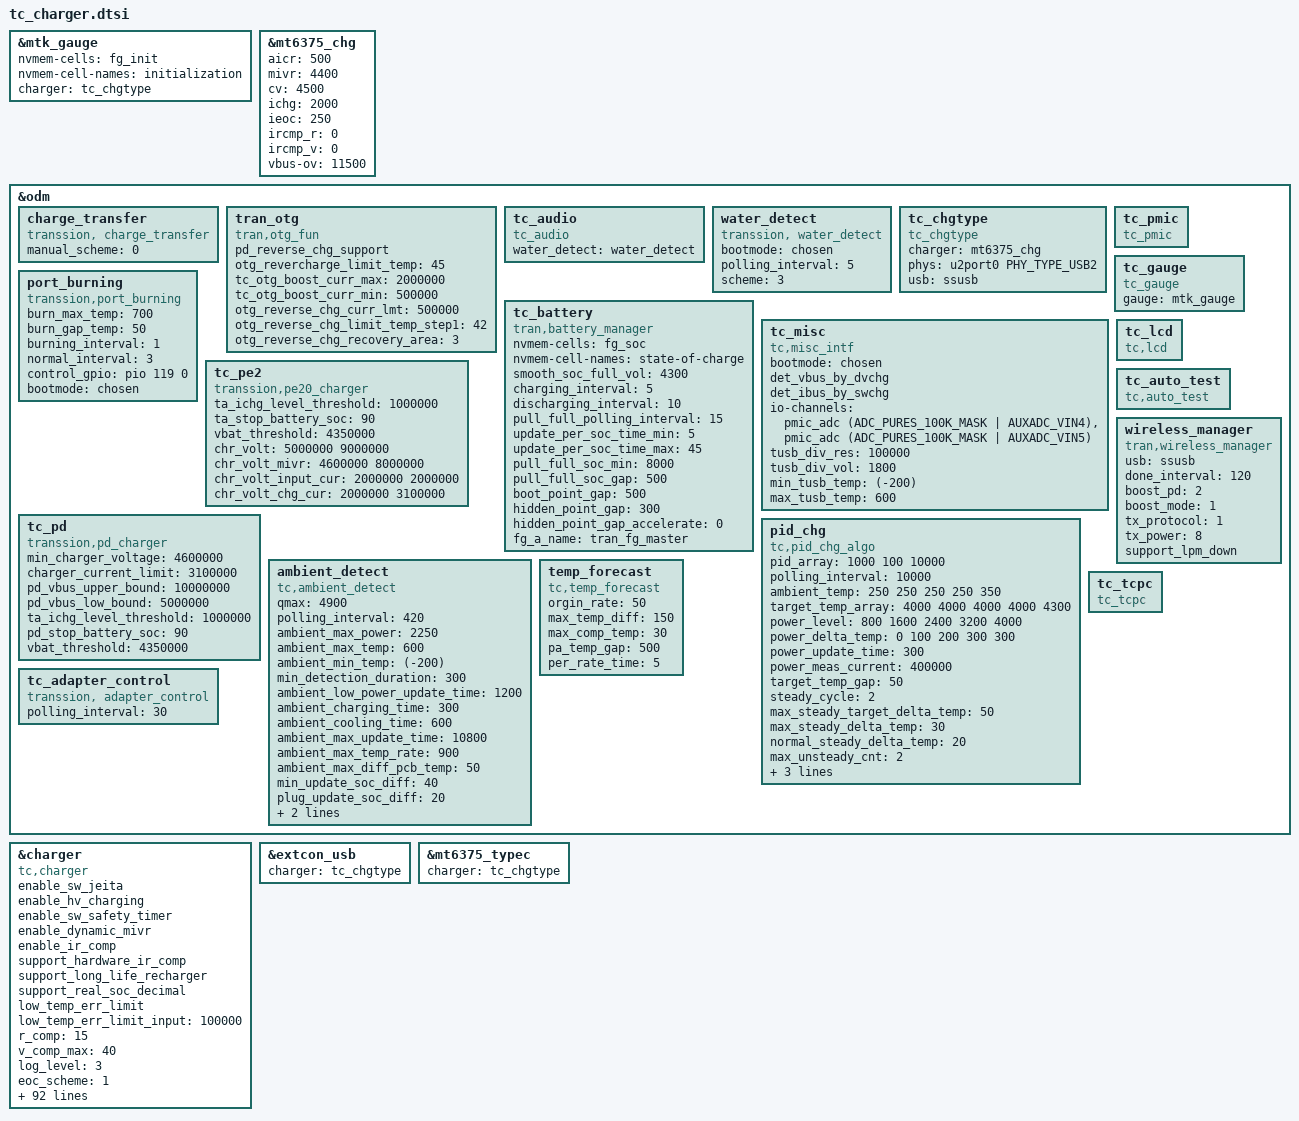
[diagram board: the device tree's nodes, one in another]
#include <dt-bindings/iio/mt635x-auxadc.h>
#include <dt-bindings/iio/adc/mediatek,mt6375_adc.h>

&mtk_gauge {
	nvmem-cells = <&fg_init>;
	nvmem-cell-names = "initialization";
};

&mt6375_chg {
	aicr = <500>;
	mivr = <4400>;
	cv = <4500>;
	ichg = <2000>;
	ieoc = <250>;
	ircmp_r = <0>;
	ircmp_v = <0>;
	vbus-ov = <11500>;
};

&odm {
	charge_transfer: charge_transfer {
		compatible = "transsion, charge_transfer";
		status = "okay";
		manual_scheme = <0>;
	};

	tran_otg: tran_otg {
		compatible = "tran,otg_fun";
		status = "okay";
		/* support_otg_dcp; */
		/* otg_dcp_by_pmic; */
		/* support_ext_otg; */
		pd_reverse_chg_support;
		otg_revercharge_limit_temp = <45>;
		tc_otg_boost_curr_max = <2000000>; /* 10W config 2000000,6W config 1200000 */
		tc_otg_boost_curr_min = <500000>;
		otg_reverse_chg_curr_lmt = <500000>;
		otg_reverse_chg_limit_temp_step1 = <42>;
		otg_reverse_chg_recovery_area = <3>;
	};

	tc_audio: tc_audio {
		compatible = "tc_audio";
		status = "okay";
		water_detect = <&water_detect>;
	};

	water_detect: water_detect {
		status = "okay";
		compatible = "transsion, water_detect";
		bootmode = <&chosen>;
		polling_interval = <5>;

		/*	0:SUBPMIC USB_ID detect
			1:GPIO detect
			2:GPIO detect--GPIO sel 1--- GPIO sel sbu1/2
			3:WAS4783 detect
			4:SUBPMIC USB_ID detect--GPIO sel 1
			5:SUBPMIC USB_ID detect--GPIO sel 1--- GPIO sel sbu1/2
		*/
		scheme = <3>;
	};

	tc_chgtype: tc_chgtype {
		compatible = "tc_chgtype";
		charger = <&mt6375_chg>;
		phys = <&u2port0 PHY_TYPE_USB2>;
		phy-names = "usb2-phy";
		usb = <&ssusb>;
		status = "okay";
	};

	tc_pmic: tc_pmic {
		compatible = "tc_pmic";
		status = "okay";
		/* The current project is not in use */
		//io-channels = <&pmic_auxadc AUXADC_VCDT>;
		//io-channel-names = "pmic_vbus";
		//pmic = <&pmic>;

		//io-channels = <&mt6375_auxadc AUXADC_VCDT>;
		//io-channels = <&mt6375_adc MT6375_ADC_CHGVIN>;
	};

	tc_gauge: tc_gauge {
		compatible = "tc_gauge";
		gauge = <&mtk_gauge>;
		status = "okay";
	};

	tc_battery: tc_battery {
		compatible = "tran,battery_manager";
		status = "okay";
		nvmem-cells = <&fg_soc>;
		nvmem-cell-names = "state-of-charge";
		smooth_soc_full_vol = <4300>;               //unit: mV
		charging_interval = <5>;                    //unit: S
		discharging_interval = <10>;                //unit: S
		pull_full_polling_interval = <15>;          //unit: S
		update_per_soc_time_min = <5>;              //unit: S
		update_per_soc_time_max = <45>;             //unit: S
		pull_full_soc_min = <8000>;                 //unit: 0.01
		pull_full_soc_gap = <500>;                  //unit: 0.01
		boot_point_gap = <500>;                     //unit: 0.01
		hidden_point_gap = <300>;                   //unit: 0.01
		hidden_point_gap_accelerate = <0>;
		fg_a_name = "tran_fg_master";
		/* dual battery  */
		/* fg_b_name = "tran_fg_slave"; */
		/* dual_fuel_gauge; */
		/* sw_cv_gap = <15>; */
		/* max_voltage_diff = <250>; */
		/* start_balance_vol_diff = <150>; */
		/* balance_step = <5>; */
		/* balance_step_cur = <500>; */
		/* min_lmt_chg_cur = <500>; */
	};

	tc_misc: tc_misc {
		compatible = "tc,misc_intf";
		bootmode = <&chosen>;
		det_vbus_by_dvchg;
		det_ibus_by_swchg;
		/* det_tusb_by_swchg; */
		io-channels = <&pmic_adc (ADC_PURES_100K_MASK | AUXADC_VIN4)>,<&pmic_adc (ADC_PURES_100K_MASK | AUXADC_VIN5)>;
		io-channel-names = "tusb","tport";
		tusb_div_res = <100000>;
		tusb_div_vol = <1800>;
		min_tusb_temp = <(-200)>;
		max_tusb_temp = <600>;
	};

	port_burning:port_burning {
		compatible = "transsion,port_burning";
		burn_max_temp = <700>;
		burn_gap_temp = <50>;
		burning_interval = <1>;
		normal_interval = <3>;
		control_gpio = <&pio 119 0>;
		bootmode= <&chosen>;
	};

	tc_lcd: tc_lcd {
		compatible = "tc,lcd";
	};

	tc_pe2:tc_pe2 {
		compatible = "transsion,pe20_charger";
		status = "okay";

		/* TC30 */
		ta_ichg_level_threshold = <1000000>; /* uA */
		ta_stop_battery_soc = <90>;
		vbat_threshold = <4350000>;

		chr_volt = <5000000 9000000>;
		chr_volt_mivr = <4600000 8000000>;
		chr_volt_input_cur = <2000000 2000000>;
		chr_volt_chg_cur = <2000000 3100000>;
	};

	tc_pd:tc_pd {
		compatible = "transsion,pd_charger";
		status = "okay";

		/* PD_FIX */
		min_charger_voltage = <4600000>; /* uV */
		charger_current_limit = <3100000>;
		pd_vbus_upper_bound = <10000000>;
		pd_vbus_low_bound = <5000000>;
		ta_ichg_level_threshold = <1000000>;
		pd_stop_battery_soc = <90>;
		vbat_threshold = <4350000>;
	};

	tc_auto_test: tc_auto_test {
	            compatible = "tc,auto_test";
	            status = "okay";
	};

	wireless_manager:wireless_manager {
		compatible = "tran,wireless_manager";
		usb = <&ssusb>;
		done_interval = <120>;
		boost_pd = <2>;
		boost_mode = /bits/ 8 <1>;
		tx_protocol = /bits/ 8 <1>;
		tx_power =  /bits/ 8 <8>;
		support_lpm_down;
		status = "okay";
	};

	pid_chg:pid_chg{
		compatible = "tc,pid_chg_algo";
		pid_array = <1000 100 10000>;           //KP KI KD
		polling_interval = <10000>;                     //The minimum time for each cycle
		ambient_temp = <250 250 250 250 350>;
		target_temp_array = <4000 4000 4000 4000 4300>;
		power_level = <800 1600 2400 3200 4000>;        //The average power consumption in the on-screen mode
		power_delta_temp = <0 100 200 300 300>;         //Temperature corresponding to the average power consumption in the on-screen mode
		power_update_time = <300>;                      //Average power update time in the on-screen mode
		power_meas_current = <400000>;                  //ibus current when the average power is measured in the on-screen mode
		target_temp_gap = <50>;
		steady_cycle = <2>;
		max_steady_target_delta_temp = <50>;
		max_steady_delta_temp = <30>;
		normal_steady_delta_temp = <20>;
		max_unsteady_cnt = <2>;
		max_target_temp = <4400>;
		//support_ibus_measure;
		ibus_measure_power_update_time = <60>;
		delta_current_max = <500000>;
	};

	ambient_detect:ambient_detect{
		compatible = "tc,ambient_detect";
		qmax = <4900>;
		polling_interval = <420>;
		ambient_max_power = <2250>;
		ambient_max_temp = <600>;
		ambient_min_temp = <(-200)>;
		min_detection_duration = <300>;
		ambient_low_power_update_time = <1200>;
		ambient_charging_time = <300>;
		ambient_cooling_time = <600>;
		ambient_max_update_time = <10800>;
		ambient_max_temp_rate = <900>;
		ambient_max_diff_pcb_temp = <50>;
		min_update_soc_diff = <40>;
		plug_update_soc_diff = <20>;
		power_level = <400 800 1200 1600 2000>;
		power_delta_temp = <0 10 20 30 40>;
	};

	temp_forecast:temp_forecast{
		compatible = "tc,temp_forecast";
		orgin_rate = <50>;
		max_temp_diff = <150>;
		max_comp_temp = <30>;
		pa_temp_gap = <500>;
		per_rate_time = <5>;
	};

	tc_tcpc:tc_tcpc{
		compatible = "tc_tcpc";
		status = "okay";
	};

	tc_adapter_control:tc_adapter_control {
		compatible = "transsion, adapter_control";
		polling_interval = <30>;
		status = "okay";
	};
};

&charger{
	compatible = "tc,charger";
	enable_sw_jeita;
	enable_hv_charging;
	enable_sw_safety_timer;
	/* charger_unlimited; */
	enable_dynamic_mivr;
	enable_ir_comp;
	/* support_reset_eoc; */
	support_hardware_ir_comp;
	support_long_life_recharger;
	support_real_soc_decimal;
	low_temp_err_limit;
	low_temp_err_limit_input = <100000>;
	r_comp = <15>;
	v_comp_max = <40>;
	log_level = <3>;
	eoc_scheme = <1>;
	aging_start_uisoc = <70>;
	aging_stop_uisoc = <75>;
	kom_start_uisoc = <40>;
	kom_stop_uisoc = <70>;
	batt_over_heat_temp = <60>;
	batt_over_cold_temp = <(-20)>;
	polling_interval = <20>;
	support_si_bat;
	si_bat_cycle_def = <100  200 99999>;
	si_bat_cycle_vol = <3000 3100 3200>;
	min_charger_voltage = <4400000>;
	min_charger_current = <1000000>;
	wireless_min_charger_current = <400000>;
	ftm_cp_num = <2>;
	sw_eoc_cv_gap = <20>;
	support_alg = "pe5", "pd", "pe20";

	tbat_temp = <(-100) 15 35 38 40 42 43 44 55 60 65 70>;
	tbat_ichg = <0 0 500000 800000 1000000 1500000 1700000 2000000 2400000 2400000 2400000 2400000>;
	tbat_temp_gap = <1>;

	tpcb_temp = <(-100) 15 30 35 37 39 41 45 55 60 65 70>;
	tpcb_ichg = <0 0 0 200000 300000 500000 700000 900000 1300000 1500000 2000000 2000000>;
	tpcb_temp_gap = <1>;

	tpa_temp = <(-100) 15 30 35 37 39 41 45 55 60 65 70>;
	tpa_ichg = <0 0 0 200000 300000 500000 700000 900000 1300000 1500000 2000000 2000000>;
	tpa_temp_gap = <1>;

	batt_ht_temp = <53 55 58>;
	batt_ht_rec_temp = <0 54 54>;
	batt_ht_code = <0  (1 << 11) (1 << 10)>;
	batt_ht_vote_hiz = <0 0 0>;
	batt_ht_vote_discharge = <0 1 1>;
	batt_ht_vote_icon = <0 1 1>;

	batt_lt_temp = <0 (-19) (-19)>;
	batt_lt_rec_temp = <0 (-17) (-17)>;
	batt_lt_code = <0 0 (1 << 12 | 1 << 7)>;
	batt_lt_vote_hiz = <0 0 0>;
	batt_lt_vote_discharge = <0 1 1>;
	batt_lt_vote_icon = <0 1 1>;

	kpoc_batt_ht_temp = <53 55 58>;
	kpoc_batt_ht_rec_temp = <0 54 54>;
	kpoc_batt_ht_code = <0 (1 << 11) (1 << 10)>;
	kpoc_batt_ht_vote_hiz = <0 0 0>;
	kpoc_batt_ht_vote_discharge = <0 1 1>;
	kpoc_batt_ht_vote_icon = <0 1 1>;

	kpoc_batt_lt_temp = <0 (-19) (-19)>;
	kpoc_batt_lt_rec_temp = <0 (-17) (-17)>;
	kpoc_batt_lt_code = <0 0 (1 << 12 | 1 << 7)>;
	kpoc_batt_lt_vote_hiz = <0 0 0>;
	kpoc_batt_lt_vote_discharge = <1 1 1>;
	kpoc_batt_lt_vote_icon = <1 1 1>;

	batt_ht_temp_dis_chg = <58 58 58>;
	batt_ht_code_dis_chg = <(1 << 10) (1 << 10) (1 << 10)>;
	batt_lt_temp_dis_chg = <(-18) (-18) (-18)>;
	batt_lt_code_dis_chg = <(1 << 7) (1 << 7) (1 << 7)>;

	dynamic_mivr_vol = <4400000 4400000 4400000 4600000>;
	charger_voltage_ovp = <6500000 10500000 20800000 20800000>;
	vbus_measure_method = <0 0 1 1>; /* depend on ovp voltage, 0:by pmic, 1:by cp ic */
	max_charging_time = <72000>; /*S 72000S= 20h*/
	sdp_charger_current = <500000>;
	sdp_input_current = <500000>;
	cdp_charger_current = <1000000>;
	cdp_input_current = <1000000>;
	dcp_charger_current = <2000000>;
	dcp_input_current = <2000000>;
	nonstd_charger_current = <1200000>;
	nonstd_input_current = <1200000>;
	max_input_current_limit = <3000000>;
	max_charging_current_limit = <3100000>;
	swchg_hw_eoc_max = <800000>;

	vbat_gap = <40000 40000 40000 40000 40000 40000>;
	single_batt_level = <6>;
	single_batt_level_0 =  <(-20)    (-10)
			(-1)
			4500000  4500000  4500000  4500000  4500000  4500000
			254000   254000   254000   254000   254000   254000
			200000
			(-1) (-1)
			0>;

	single_batt_level_1 =  <(-10)    0
			(-1)
			4500000  4500000  4500000  4500000  4500000  4500000
			508000  508000   508000   508000   508000   508000
			254000
			(-1) (-1)
			0>;

	single_batt_level_2 =  <0        10
			(-1)
			4500000  4500000  4500000  4500000  4500000  4500000
			1016000  1016000  1016000  1016000  1016000  1016000
			254000
			(-1) (-1)
			0>;

	single_batt_level_3 =  <10       15
			(-1)
			4500000  4500000  4500000  4500000  4500000  4500000
			3100000  3100000  3100000  3100000  3100000  3100000
			254000
			(-1) (-1)
			0>;

	single_batt_level_4 =  <15       45
			(-1)
			4500000  4500000  4500000  4500000  4500000  4500000
			3100000  3100000  3100000  3100000  3100000  3100000
			254000
			(-1) (-1)
			0>;

	single_batt_level_5 =  <45       60
			(-1)
			4200000  4200000  4200000  4200000  4200000  4200000
			2540000  2540000  2540000  2540000  2540000  2540000
			254000
			(-1) (-1)
			0>;

/*	single_batt_level_5 =  <(-20)    (-10)*/
/*			4500000  4500000  4500000  4500000  4500000  4500000*/
/*			900000   900000   900000   900000   900000   900000*/
/*			225000*/
/*			300 (-1)*/
/*			20>;*/

	/* only for dual switch*/
	/* support_dual_switch; */
	/* dsc_chg1_high_cv; */
	/* dsc_eoc_cur = <500000>; */
	/* dsc_aicr_min = <1000000>; */
	/* dsc_ichg_min = <1400000>; */
	/* chg_tab = < */
	/*         3400000 1700000 */
	/*         3300000 1600000 */
	/*         3200000 1600000 */
	/*         3100000 1500000 */
	/*         3000000 1500000 */
	/*         2900000 1400000 */
	/*         2800000 1400000 */
	/*         2700000 1300000 */
	/*         2600000 1300000 */
	/*         2500000 1200000 */
	/*         2400000 1200000 */
	/*         2300000 1100000 */
	/*         2200000 1100000 */
	/*         2100000 1000000 */
	/*         2000000 1000000 */
	/*         1900000 900000 */
	/*         1800000 900000 */
	/*         1700000 800000 */
	/*         1600000 800000 */
	/*         1500000 700000 */
	/*         1400000 700000 */
	/*         1300000 600000 */
	/*         1200000 600000 */
	/*         1100000 500000 */
	/*         1000000 500000 */
	/*         900000 400000 */
	/*         800000 400000 */
	/*         700000 300000 */
	/*         600000 300000 */
	/*         500000 200000 */
	/*         400000 200000 */
	/*         300000 100000 */
	/*         200000 100000 */
	/*         100000 0 */
	/*>;*/

	/* only for dual battery */

	/* master_r_comp = <10>; */
	/* master_v_comp_max = <20>; */
	/* slave_r_comp = <10>; */
	/* slave_v_comp_max = <20>; */
	/* support_dual_battery; */
	/* dual_batt_eoc_delay_time = <15>; */
	/* master_batt_level = <2>; */
	/* master_batt_level_0 =  <(-20)    (0) */
	/*                         4500000  4500000  4500000  4500000  4500000  4500000 */
	/*                         900000   900000   900000   900000   900000   900000 */
	/*                         225000>; */

	/* master_batt_level_1 =  <0        50 */
	/*                         4200000  4500000  4500000  4500000  4500000  4500000 */
	/*                         9000000  5400000  5400000  5400000  5400000  5400000 */
	/*                         225000>; */

	/* slave_batt_level = <2>; */
	/* slave_batt_level_0 =  <(-20)    (0) */
	/*                         4500000  4500000  4500000  4500000  4500000  4500000 */
	/*                         900000   900000   900000   900000   900000   900000 */
	/*                         225000>; */

	/* slave_batt_level_1 =  <0        50 */
	/*                         4200000  4500000  4500000  4500000  4500000  4500000 */
	/*                         9000000  5400000  5400000  5400000  5400000  5400000 */
	/*                         225000>; */

};

&extcon_usb {
	charger = <&tc_chgtype>;
};

&mtk_gauge {
	charger = <&tc_chgtype>;
};

&mt6375_typec {
	charger = <&tc_chgtype>;
};
